# ELM_ELM_25010000h register map
Vendor: Texas Instruments
Peripheral module from a debugger description file (folder am62L).
Registers are 32-bit, read-only, reset values left out (the file's numbers can be read two ways) unless marked. A register's access mark holds for its fields unless they carry their own. Offsets are as the file gives them; lines under a group give offsets from that group; [hi:lo] are bit positions; {n}, {i} and the like mark numbered series; 'fields as' and 'values as' point back to an identical list; <NAME> marks a mode.

## elm
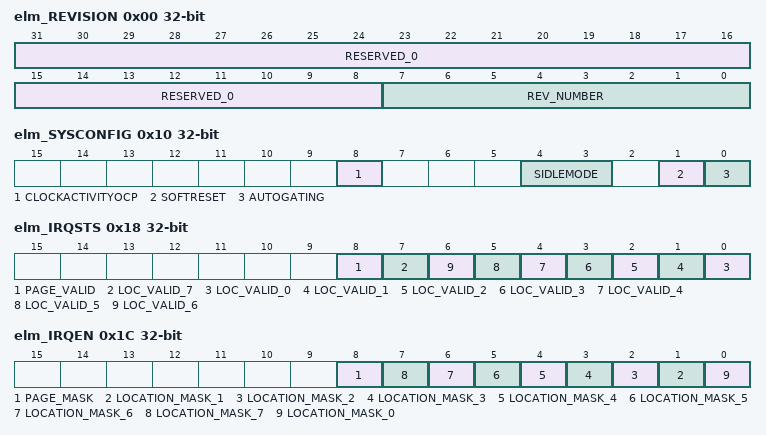
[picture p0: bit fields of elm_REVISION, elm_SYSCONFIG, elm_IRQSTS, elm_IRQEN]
0x00 elm_REVISION — This register contains the IP revision code.(A write to this register has no effect, the same as the reset)
  [31:8] RESERVED_0 — Read returns 0
  [7:0] REV_NUMBER — IP revision number [RTL] [7:4] Major revision [3:0] Minor revision Reset Source: mod_g_arst_n
0x10 elm_SYSCONFIG rw — This register allows controlling various parameters of the OCP interface
  [8] CLOCKACTIVITYOCP — OCP Clock activity when module is in IDLE mode [during wake up mode period] Reset Source: mod_g_arst_n
  [4:3] SIDLEMODE — Target interface power management [IDLE req/ack control] Reset Source: mod_g_arst_n
  [1] SOFTRESET — Module Software Reset The bit is automatically reset by the hardware [During reads, it always returns 0] It has same effect as the OCP Hardware reset Reset Source: mod_g_arst_n
  [0] AUTOGATING — Internal OCP clock gating strategy [no module visible impact other than saving power] Reset Source: mod_g_arst_n
0x14 elm_SYSSTS — Internal Reset monitoring (OCP domain)Undefined since:on HW perspective reset state is 0on SW user perspective when module is accessible is 1
  [0] RESETDONE — Internal Reset monitoring [OCP domain] Undefined since: on HW perspective reset state is 0 on SW user perspective when module is accessible is 1 Reset Source: mod_g_arst_n
0x18 elm_IRQSTS access not given — Interrupt status. This register doubles as a status register for the error location processes.
  [8] PAGE_VALID — Error location status for a full page, based on the mask definition Read 0x0: error locations invalid for all polynomials enabled in the ECC_INTERRUPT_MASK register Read 0x1: all error locations valid Write 0x0: no effect Write 0x1: clear interrupt Reset Source: mod_g_arst_n (access R/W1TC)
  [7] LOC_VALID_7 — Error location status for syndrome polynomial 7 Read 0x0: no syndrome processed or process in progress Read 0x1: error location process completed Write 0x0: no effect Write 0x1: clear interrupt Reset Source: mod_g_arst_n (access R/W1TC)
  [n] LOC_VALID_{n} (n=0..6) — Error location status for syndrome polynomial {n} Reset Source: mod_g_arst_n (access R/W1TC)
0x1C elm_IRQEN rw — Interrupt enable
  [8] PAGE_MASK — Page interrupt mask bit 0: disable interrupt 1: enable interrupt Reset Source: mod_g_arst_n
  [n] LOCATION_MASK_{n} (n=1..7) — Error location interrupt mask bit for syndrome polynomial {n} Reset Source: mod_g_arst_n
  [0] LOCATION_MASK_0 — Error location interrupt mask bit for syndrome polynomial 0 0: disable interrupt 1: enable interrupt Reset Source: mod_g_arst_n
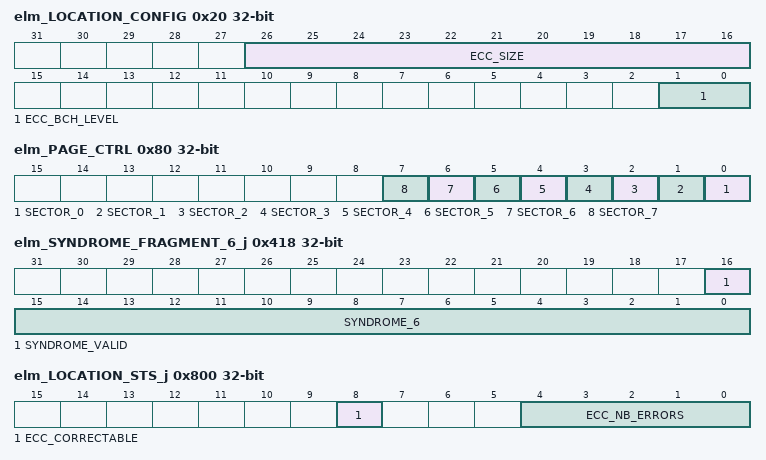
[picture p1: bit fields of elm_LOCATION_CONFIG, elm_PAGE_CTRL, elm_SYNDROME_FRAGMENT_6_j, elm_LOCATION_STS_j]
0x20 elm_LOCATION_CONFIG rw — ECC algorithm parameters
  [26:16] ECC_SIZE — Maximum size of the buffers for which the error location engine is used, in number of nibbles [4-bits entities] Reset Source: mod_g_arst_n
  [1:0] ECC_BCH_LEVEL — Error correction level 0x0: 4 bits 0x1: 8 bits 0x2: 16 bits 0x3: reserved Reset Source: mod_g_arst_n
0x80 elm_PAGE_CTRL rw — Page definition
  [n] SECTOR_{n} (n=0..7) — Set to 1 if syndrome polynomial {n} is part of the page in page mode Must be 0 in continuous mode Reset Source: mod_g_arst_n
{0x400+4i} elm_SYNDROME_FRAGMENT_{i}_j rw (i=0..2) — Input syndrome polynomial bits {32i} to {32i+31}.
  [31:0] SYNDROME_{i} — Syndrome bits {32i} to {32i+31} Reset Source: mod_g_arst_n
0x40C elm_SYNDROME_FRAGMENT_3_j rw — Input syndrome polynomial bits 96 to 127
  [31:0] SYNDROME_3 — Syndrome bits 96 to 127 Reset Source: mod_g_arst_n
0x410 elm_SYNDROME_FRAGMENT_4_j rw — Input syndrome polynomial bits 128 to 159.
  [31:0] SYNDROME_4 — Syndrome bits 128 to 159 Reset Source: mod_g_arst_n
0x414 elm_SYNDROME_FRAGMENT_5_j rw — Input syndrome polynomial bits 160 to 191.
  [31:0] SYNDROME_5 — Syndrome bits 160 to 191 Reset Source: mod_g_arst_n
0x418 elm_SYNDROME_FRAGMENT_6_j rw — Input syndrome polynomial bits 192 to 207.
  [16] SYNDROME_VALID — Syndrome valid bit 0x0: this syndrome polynomial should not be processed 0x1: this syndrome polynomial must be processed Reset Source: mod_g_arst_n
  [15:0] SYNDROME_6 — Syndrome bits 192 to 207 Reset Source: mod_g_arst_n
0x800 elm_LOCATION_STS_j — Exit status for the syndrome polynomial processing
  [8] ECC_CORRECTABLE — Error location process exit status 0x0: ECC error location process failed Number of errors and error locations are invalid 0x1: all errors were successfully located Number of errors and error locations are valid Reset Source: mod_g_arst_n
  [4:0] ECC_NB_ERRORS — Number of errors detected and located Reset Source: mod_g_arst_n
{0x880+4i} elm_ERROR_LOCATION_{i}_j (i=0..15) — Error location register
  [12:0] ECC_ERROR_LOCATION — Error location bit address Reset Source: mod_g_arst_n
